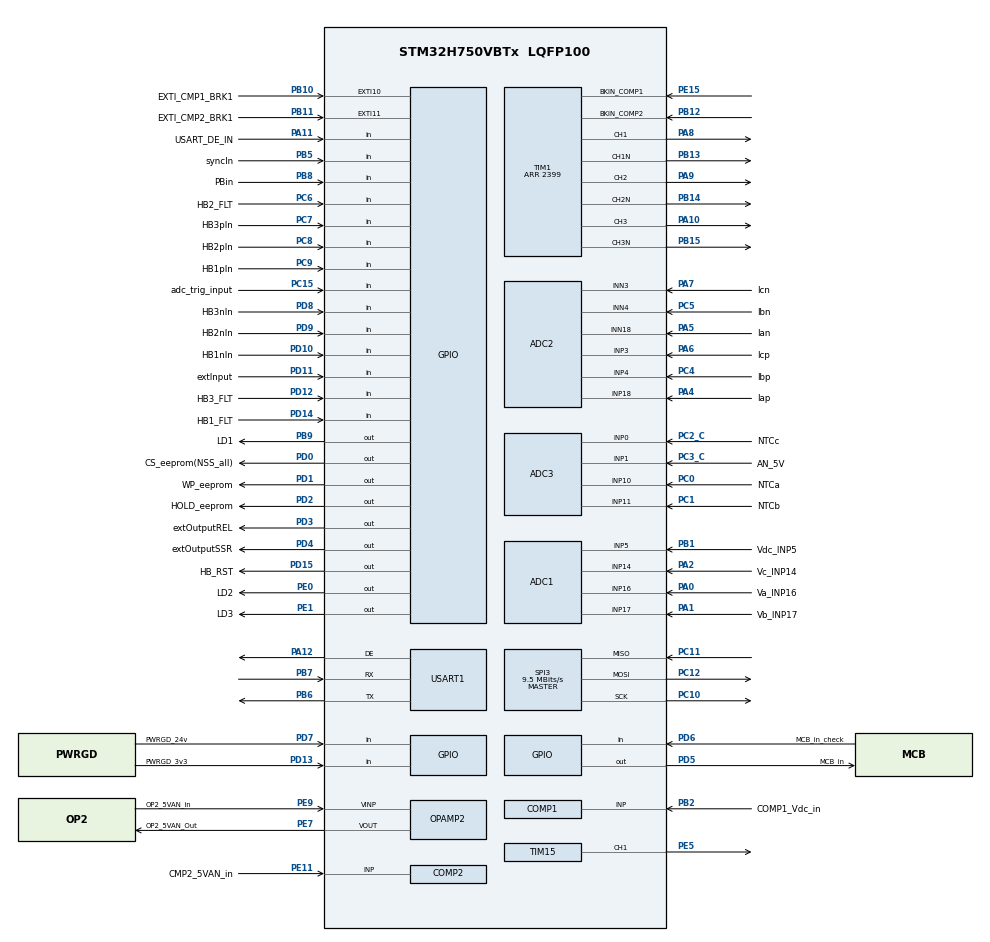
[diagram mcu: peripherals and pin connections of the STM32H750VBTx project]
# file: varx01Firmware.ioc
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ADC1.Channel-1\#ChannelRegularConversion=ADC_CHANNEL_16
ADC1.Channel-2\#ChannelRegularConversion=ADC_CHANNEL_17
ADC1.Channel-3\#ChannelRegularConversion=ADC_CHANNEL_14
ADC1.Channel-4\#ChannelRegularConversion=ADC_CHANNEL_5
ADC1.ConversionDataManagement=ADC_CONVERSIONDATA_DMA_CIRCULAR
ADC1.DMAAccessModeView=ENABLE
ADC1.EOCSelection=ADC_EOC_SEQ_CONV
ADC1.EnableAnalogWatchDog1=false
ADC1.ExternalTrigConv=ADC_EXTERNALTRIG_T2_TRGO
ADC1.Mode=ADC_DUALMODE_REGSIMULT
ADC1.NbrOfConversion=4
ADC1.NbrOfConversionFlag=1
ADC1.OffsetNumber-1\#ChannelRegularConversion=ADC_OFFSET_NONE
ADC1.OffsetNumber-2\#ChannelRegularConversion=ADC_OFFSET_NONE
ADC1.OffsetNumber-3\#ChannelRegularConversion=ADC_OFFSET_NONE
ADC1.OffsetNumber-4\#ChannelRegularConversion=ADC_OFFSET_NONE
ADC1.OffsetSignedSaturation-2\#ChannelRegularConversion=DISABLE
ADC1.OffsetSignedSaturation-3\#ChannelRegularConversion=DISABLE
ADC1.OffsetSignedSaturation-4\#ChannelRegularConversion=DISABLE
ADC1.Overrun=ADC_OVR_DATA_OVERWRITTEN
ADC1.OversamplingMode=ENABLE
ADC1.Rank-1\#ChannelRegularConversion=1
ADC1.Rank-2\#ChannelRegularConversion=2
ADC1.Rank-3\#ChannelRegularConversion=3
ADC1.Rank-4\#ChannelRegularConversion=4
ADC1.Ratio=4
ADC1.RightBitShift=ADC_RIGHTBITSHIFT_2
ADC1.SamplingTime-1\#ChannelRegularConversion=ADC_SAMPLETIME_16CYCLES_5
ADC1.SamplingTime-2\#ChannelRegularConversion=ADC_SAMPLETIME_16CYCLES_5
ADC1.SamplingTime-3\#ChannelRegularConversion=ADC_SAMPLETIME_16CYCLES_5
ADC1.SamplingTime-4\#ChannelRegularConversion=ADC_SAMPLETIME_16CYCLES_5
ADC1.master=1
ADC2.AWD1HighThreshold=158368
ADC2.AWD1ITMode=ENABLE
ADC2.AWD1LowThreshold=103771
ADC2.Channel-0\#ChannelRegularConversion=ADC_CHANNEL_18
ADC2.Channel-1\#ChannelRegularConversion=ADC_CHANNEL_4
ADC2.Channel-2\#ChannelRegularConversion=ADC_CHANNEL_3
ADC2.Channel-3\#ChannelRegularConversion=ADC_CHANNEL_18
ADC2.DMAAccessModeView=ENABLE
ADC2.EOCSelection=ADC_EOC_SEQ_CONV
ADC2.EnableAnalogWatchDog1=true
ADC2.Mode=ADC_DUALMODE_REGSIMULT
ADC2.NbrOfConversion=4
ADC2.NbrOfConversionFlag=1
ADC2.OffsetNumber-0\#ChannelRegularConversion=ADC_OFFSET_NONE
ADC2.OffsetNumber-1\#ChannelRegularConversion=ADC_OFFSET_NONE
ADC2.OffsetNumber-2\#ChannelRegularConversion=ADC_OFFSET_NONE
ADC2.OffsetNumber-3\#ChannelRegularConversion=ADC_OFFSET_NONE
ADC2.OffsetSignedSaturation-1\#ChannelRegularConversion=DISABLE
ADC2.OffsetSignedSaturation-2\#ChannelRegularConversion=DISABLE
ADC2.OffsetSignedSaturation-3\#ChannelRegularConversion=DISABLE
ADC2.Overrun=ADC_OVR_DATA_OVERWRITTEN
ADC2.OversamplingMode=ENABLE
ADC2.Rank-0\#ChannelRegularConversion=1
ADC2.Rank-1\#ChannelRegularConversion=2
ADC2.Rank-2\#ChannelRegularConversion=3
ADC2.Rank-3\#ChannelRegularConversion=4
ADC2.Ratio=4
ADC2.RightBitShift=ADC_RIGHTBITSHIFT_2
ADC2.SamplingTime-0\#ChannelRegularConversion=ADC_SAMPLETIME_16CYCLES_5
ADC2.SamplingTime-1\#ChannelRegularConversion=ADC_SAMPLETIME_16CYCLES_5
ADC2.SamplingTime-2\#ChannelRegularConversion=ADC_SAMPLETIME_16CYCLES_5
ADC2.SamplingTime-3\#ChannelRegularConversion=ADC_SAMPLETIME_16CYCLES_5
ADC2.SingleDiff-0\#ChannelRegularConversion=ADC_DIFFERENTIAL_ENDED
ADC2.SingleDiff-1\#ChannelRegularConversion=ADC_DIFFERENTIAL_ENDED
ADC2.SingleDiff-2\#ChannelRegularConversion=ADC_DIFFERENTIAL_ENDED
ADC2.SingleDiff-3\#ChannelRegularConversion=ADC_DIFFERENTIAL_ENDED
ADC2.WatchdogMode=ADC_ANALOGWATCHDOG_ALL_REG
ADC3.Channel-0\#ChannelRegularConversion=ADC_CHANNEL_10
ADC3.Channel-1\#ChannelRegularConversion=ADC_CHANNEL_11
ADC3.Channel-2\#ChannelRegularConversion=ADC_CHANNEL_0
ADC3.Channel-3\#ChannelRegularConversion=ADC_CHANNEL_1
ADC3.ClockPrescaler=ADC_CLOCK_ASYNC_DIV1
ADC3.ConversionDataManagement=ADC_CONVERSIONDATA_DMA_CIRCULAR
ADC3.EOCSelection=ADC_EOC_SEQ_CONV
ADC3.EnableAnalogWatchDog1=false
ADC3.ExternalTrigConv=ADC_EXTERNALTRIG_T4_TRGO
ADC3.NbrOfConversion=4
ADC3.NbrOfConversionFlag=1
ADC3.OffsetNumber-0\#ChannelRegularConversion=ADC_OFFSET_NONE
ADC3.OffsetNumber-1\#ChannelRegularConversion=ADC_OFFSET_NONE
ADC3.OffsetNumber-2\#ChannelRegularConversion=ADC_OFFSET_NONE
ADC3.OffsetNumber-3\#ChannelRegularConversion=ADC_OFFSET_NONE
ADC3.OffsetSignedSaturation-1\#ChannelRegularConversion=DISABLE
ADC3.OffsetSignedSaturation-2\#ChannelRegularConversion=DISABLE
ADC3.OffsetSignedSaturation-3\#ChannelRegularConversion=DISABLE
ADC3.Overrun=ADC_OVR_DATA_OVERWRITTEN
ADC3.OversamplingMode=ENABLE
ADC3.Rank-0\#ChannelRegularConversion=1
ADC3.Rank-1\#ChannelRegularConversion=2
ADC3.Rank-2\#ChannelRegularConversion=3
ADC3.Rank-3\#ChannelRegularConversion=4
ADC3.Ratio=4
ADC3.RightBitShift=ADC_RIGHTBITSHIFT_2
ADC3.SamplingTime-0\#ChannelRegularConversion=ADC_SAMPLETIME_16CYCLES_5
ADC3.SamplingTime-1\#ChannelRegularConversion=ADC_SAMPLETIME_16CYCLES_5
ADC3.SamplingTime-2\#ChannelRegularConversion=ADC_SAMPLETIME_16CYCLES_5
ADC3.SamplingTime-3\#ChannelRegularConversion=ADC_SAMPLETIME_16CYCLES_5
COMP1.TriggerMode=COMP_TRIGGERMODE_IT_RISING
COMP2.TriggerMode=COMP_TRIGGERMODE_IT_RISING
CORTEX_M7.CPU_DCache=Enabled
CORTEX_M7.CPU_ICache=Enabled
DAC1.DAC_Channel-DAC_OUT1_Int=DAC_CHANNEL_1
DAC1.DAC_Channel-DAC_OUT2_Int=DAC_CHANNEL_2
Dma.ADC1.0.Direction=DMA_PERIPH_TO_MEMORY
Dma.ADC1.0.EventEnable=DISABLE
Dma.ADC1.0.FIFOMode=DMA_FIFOMODE_DISABLE
Dma.ADC1.0.Instance=DMA1_Stream0
Dma.ADC1.0.MemDataAlignment=DMA_MDATAALIGN_WORD
Dma.ADC1.0.MemInc=DMA_MINC_ENABLE
Dma.ADC1.0.Mode=DMA_CIRCULAR
Dma.ADC1.0.PeriphDataAlignment=DMA_PDATAALIGN_WORD
Dma.ADC1.0.PeriphInc=DMA_PINC_DISABLE
Dma.ADC1.0.Polarity=HAL_DMAMUX_REQ_GEN_RISING
Dma.ADC1.0.Priority=DMA_PRIORITY_VERY_HIGH
Dma.ADC1.0.RequestNumber=1
Dma.ADC1.0.SignalID=NONE
Dma.ADC1.0.SyncEnable=DISABLE
Dma.ADC1.0.SyncPolarity=HAL_DMAMUX_SYNC_NO_EVENT
Dma.ADC1.0.SyncRequestNumber=1
Dma.ADC1.0.SyncSignalID=NONE
Dma.ADC3.1.Direction=DMA_PERIPH_TO_MEMORY
Dma.ADC3.1.EventEnable=DISABLE
Dma.ADC3.1.FIFOMode=DMA_FIFOMODE_DISABLE
Dma.ADC3.1.Instance=DMA2_Stream1
Dma.ADC3.1.MemDataAlignment=DMA_MDATAALIGN_WORD
Dma.ADC3.1.MemInc=DMA_MINC_ENABLE
Dma.ADC3.1.Mode=DMA_CIRCULAR
Dma.ADC3.1.PeriphDataAlignment=DMA_PDATAALIGN_WORD
Dma.ADC3.1.PeriphInc=DMA_PINC_DISABLE
Dma.ADC3.1.Polarity=HAL_DMAMUX_REQ_GEN_RISING
Dma.ADC3.1.Priority=DMA_PRIORITY_LOW
Dma.ADC3.1.RequestNumber=1
Dma.ADC3.1.SignalID=NONE
Dma.ADC3.1.SyncEnable=DISABLE
Dma.ADC3.1.SyncPolarity=HAL_DMAMUX_SYNC_NO_EVENT
Dma.ADC3.1.SyncRequestNumber=1
Dma.ADC3.1.SyncSignalID=NONE
Dma.Request0=ADC1
Dma.Request1=ADC3
Mcu.Family=STM32H7
Mcu.Name=STM32H750VBTx
Mcu.Package=LQFP100
NVIC.COMP_IRQn=true\:0\:0\:false\:false\:true\:false\:true
NVIC.DMA1_Stream0_IRQn=true\:0\:0\:false\:false\:true\:false\:true
NVIC.DMA2_Stream1_IRQn=true\:0\:0\:false\:false\:true\:false\:true
NVIC.PriorityGroup=NVIC_PRIORITYGROUP_4
NVIC.TIM1_BRK_IRQn=true\:0\:0\:false\:false\:true\:true\:true
NVIC.TIM1_CC_IRQn=true\:0\:0\:false\:false\:true\:true\:true
NVIC.TIM2_IRQn=true\:0\:0\:false\:false\:true\:true\:true
NVIC.TIM4_IRQn=true\:0\:0\:false\:false\:true\:true\:true
PA0.GPIO_Label=Va_INP16
PA0.Mode=IN16-Single-Ended
PA0.Signal=ADC1_INP16
PA1.GPIO_Label=Vb_INP17
PA1.Mode=IN17-Single-Ended
PA1.Signal=ADC1_INP17
PA10.Signal=S_TIM1_CH3
PA11.GPIO_Label=USART_DE_IN
PA11.Signal=GPIO_Input
PA12.Mode=Hardware Flow Control (RS485)
PA12.Signal=USART1_DE
PA13\ (JTMS/SWDIO).Mode=JTAG_5_pins
PA13\ (JTMS/SWDIO).Signal=DEBUG_JTMS-SWDIO
PA14\ (JTCK/SWCLK).Mode=JTAG_5_pins
PA14\ (JTCK/SWCLK).Signal=DEBUG_JTCK-SWCLK
PA15\ (JTDI).GPIO_Label=DEBUG_JTDI(SPI3_NSS)
PA15\ (JTDI).Mode=JTAG_5_pins
PA15\ (JTDI).Signal=DEBUG_JTDI
PA2.GPIO_Label=Vc_INP14
PA2.Signal=ADCx_INP14
PA4.GPIO_Label=Iap
PA4.Signal=ADCx_INP18
PA5.GPIO_Label=Ian
PA5.Signal=ADCx_INN18
PA6.GPIO_Label=Icp
PA6.Signal=ADCx_INP3
PA7.GPIO_Label=Icn
PA7.Signal=ADCx_INN3
PA8.Signal=S_TIM1_CH1
PA9.Signal=S_TIM1_CH2
PB1.GPIO_Label=Vdc_INP5
PB1.Signal=ADCx_INP5
PB10.GPIO_Label=EXTI_CMP1_BRK1
PB10.Signal=GPXTI10
PB11.GPIO_Label=EXTI_CMP2_BRK1
PB11.Signal=GPXTI11
PB12.Mode=ExternalOutput_TIM1BKIN
PB12.Signal=TIM1_BKIN_COMP2
PB13.Mode=PWM Generation1 CH1 CH1N
PB13.Signal=TIM1_CH1N
PB14.Mode=PWM Generation2 CH2 CH2N
PB14.Signal=TIM1_CH2N
PB15.Mode=PWM Generation3 CH3 CH3N
PB15.Signal=TIM1_CH3N
PB2.GPIO_Label=COMP1_Vdc_in
PB2.Mode=INP
PB2.Signal=COMP1_INP
PB3\ (JTDO/TRACESWO).Mode=JTAG_5_pins
PB3\ (JTDO/TRACESWO).Signal=DEBUG_JTDO-SWO
PB4\ (NJTRST).Mode=JTAG_5_pins
PB4\ (NJTRST).Signal=DEBUG_JTRST
PB5.GPIO_Label=syncIn
PB5.Signal=GPIO_Input
PB6.Mode=Asynchronous
PB6.Signal=USART1_TX
PB7.Mode=Asynchronous
PB7.Signal=USART1_RX
PB8.GPIO_Label=PBin
PB8.Signal=GPIO_Input
PB9.GPIO_Label=LD1
PB9.Signal=GPIO_Output
PC0.GPIO_Label=NTCa
PC0.Signal=ADCx_INP10
PC1.GPIO_Label=NTCb
PC1.Signal=ADCx_INP11
PC10.Mode=Full_Duplex_Master
PC10.Signal=SPI3_SCK
PC11.Mode=Full_Duplex_Master
PC11.Signal=SPI3_MISO
PC12.Mode=Full_Duplex_Master
PC12.Signal=SPI3_MOSI
PC15-OSC32_OUT\ (OSC32_OUT).GPIO_Label=adc_trig_input
PC15-OSC32_OUT\ (OSC32_OUT).Signal=GPIO_Input
PC2_C.GPIO_Label=NTCc
PC2_C.Mode=IN0-Single-Ended
PC2_C.Signal=ADC3_INP0
PC3_C.GPIO_Label=AN_5V
PC3_C.Mode=IN1-Single-Ended
PC3_C.Signal=ADC3_INP1
PC4.GPIO_Label=Ibp
PC4.Signal=ADCx_INP4
PC5.GPIO_Label=Ibn
PC5.Signal=ADCx_INN4
PC6.GPIO_Label=HB2_FLT
PC6.Signal=GPIO_Input
PC7.GPIO_Label=HB3pIn
PC7.Signal=GPIO_Input
PC8.GPIO_Label=HB2pIn
PC8.Signal=GPIO_Input
PC9.GPIO_Label=HB1pIn
PC9.Signal=GPIO_Input
PD0.GPIO_Label=CS_eeprom(NSS_all)
PD0.Signal=GPIO_Output
PD1.GPIO_Label=WP_eeprom
PD1.Signal=GPIO_Output
PD10.GPIO_Label=HB1nIn
PD10.Signal=GPIO_Input
PD11.GPIO_Label=extInput
PD11.Signal=GPIO_Input
PD12.GPIO_Label=HB3_FLT
PD12.Signal=GPIO_Input
PD13.GPIO_Label=PWRGD_3v3
PD13.Signal=GPIO_Input
PD14.GPIO_Label=HB1_FLT
PD14.Signal=GPIO_Input
PD15.GPIO_Label=HB_RST
PD15.Signal=GPIO_Output
PD2.GPIO_Label=HOLD_eeprom
PD2.Signal=GPIO_Output
PD3.GPIO_Label=extOutputREL
PD3.Signal=GPIO_Output
PD4.GPIO_Label=extOutputSSR
PD4.Signal=GPIO_Output
PD5.GPIO_Label=MCB_in
PD5.Signal=GPIO_Output
PD6.GPIO_Label=MCB_in_check
PD6.Signal=GPIO_Input
PD7.GPIO_Label=PWRGD_24v
PD7.Signal=GPIO_Input
PD8.GPIO_Label=HB3nIn
PD8.Signal=GPIO_Input
PD9.GPIO_Label=HB2nIn
PD9.Signal=GPIO_Input
PE0.GPIO_Label=LD2
PE0.Signal=GPIO_Output
PE1.GPIO_Label=LD3
PE1.Signal=GPIO_Output
PE11.GPIO_Label=CMP2_5VAN_in
PE11.Mode=INP
PE11.Signal=COMP2_INP
PE15.Mode=ExternalOutput_TIM1BKIN
PE15.Signal=TIM1_BKIN_COMP1
PE5.Signal=S_TIM15_CH1
PE7.GPIO_Label=OP2_5VAN_Out
PE7.Mode=Follower
PE7.Signal=OPAMP2_VOUT
PE9.GPIO_Label=OP2_5VAN_in
PE9.Mode=Follower
PE9.Signal=OPAMP2_VINP
PH0-OSC_IN\ (PH0).Mode=HSE-External-Oscillator
PH0-OSC_IN\ (PH0).Signal=RCC_OSC_IN
PH1-OSC_OUT\ (PH1).Mode=HSE-External-Oscillator
PH1-OSC_OUT\ (PH1).Signal=RCC_OSC_OUT
ProjectManager.HeapSize=0x200
ProjectManager.StackSize=0x400
ProjectManager.TargetToolchain=MDK-ARM V5
RCC.ADCFreq_Value=76000000
RCC.APB1Freq_Value=120000000
RCC.APB2Freq_Value=120000000
RCC.APB3Freq_Value=120000000
RCC.APB4Freq_Value=120000000
RCC.CortexFreq_Value=480000000
RCC.D1PPRE=RCC_APB3_DIV2
RCC.D2PPRE1=RCC_APB1_DIV2
RCC.D2PPRE2=RCC_APB2_DIV2
RCC.D3PPRE=RCC_APB4_DIV2
RCC.DIVM1=1
RCC.DIVM2=1
RCC.DIVM3=1
RCC.DIVN1=120
RCC.DIVN2=19
RCC.DIVN3=32
RCC.DIVQ2=1
RCC.HCLKFreq_Value=240000000
RCC.HPRE=RCC_HCLK_DIV2
RCC.HSE_VALUE=8000000
RCC.PLL2FRACN=0
RCC.PLLSourceVirtual=RCC_PLLSOURCE_HSE
RCC.SPI123CLockSelection=RCC_SPI123CLKSOURCE_PLL2
RCC.SYSCLKFreq_VALUE=480000000
RCC.SYSCLKSource=RCC_SYSCLKSOURCE_PLLCLK
RCC.USBFreq_Value=480000000
SH.ADCx_INN18.0=ADC2_INN18,IN18-Differential
SH.ADCx_INN3.0=ADC2_INN3,IN3-Differential
SH.ADCx_INN4.0=ADC2_INN4,IN4-Differential
SH.ADCx_INP10.0=ADC3_INP10,IN10-Single-Ended
SH.ADCx_INP11.0=ADC3_INP11,IN11-Single-Ended
SH.ADCx_INP14.0=ADC1_INP14,IN14-Single-Ended
SH.ADCx_INP18.0=ADC2_INP18,IN18-Differential
SH.ADCx_INP3.0=ADC2_INP3,IN3-Differential
SH.ADCx_INP4.0=ADC2_INP4,IN4-Differential
SH.ADCx_INP5.0=ADC1_INP5,IN5-Single-Ended
SH.S_TIM15_CH1.0=TIM15_CH1,Output Compare1 CH1
SH.S_TIM1_CH1.0=TIM1_CH1,PWM Generation1 CH1 CH1N
SH.S_TIM1_CH2.0=TIM1_CH2,PWM Generation2 CH2 CH2N
SH.S_TIM1_CH3.0=TIM1_CH3,PWM Generation3 CH3 CH3N
SPI3.BaudRatePrescaler=SPI_BAUDRATEPRESCALER_8
SPI3.CalculateBaudRate=9.5 MBits/s
SPI3.Direction=SPI_DIRECTION_2LINES
SPI3.Mode=SPI_MODE_MASTER
SPI3.VirtualType=VM_MASTER
TIM1.AutoReloadPreload=TIM_AUTORELOAD_PRELOAD_ENABLE
TIM1.AutomaticOutput=TIM_AUTOMATICOUTPUT_ENABLE
TIM1.BreakState=TIM_BREAK_DISABLE
TIM1.Channel-PWM\ Generation1\ CH1\ CH1N=TIM_CHANNEL_1
TIM1.Channel-PWM\ Generation2\ CH2\ CH2N=TIM_CHANNEL_2
TIM1.Channel-PWM\ Generation3\ CH3\ CH3N=TIM_CHANNEL_3
TIM1.CounterMode=TIM_COUNTERMODE_CENTERALIGNED1
TIM1.DeadTime=30
TIM1.OffStateIDLEMode=TIM_OSSI_DISABLE
TIM1.OffStateRunMode=TIM_OSSR_DISABLE
TIM1.Period=2399
TIM1.SourceBRKCOMP1=TIM_BREAKINPUTSOURCE_DISABLE
TIM1.SourceBRKCOMP2=TIM_BREAKINPUTSOURCE_ENABLE
TIM1.SourceBRKCOMP2Polarity=TIM_BREAKINPUTSOURCE_POLARITY_HIGH
TIM15.Channel-Output\ Compare1\ CH1=TIM_CHANNEL_1
TIM2.Period=4799
TIM2.TIM_MasterOutputTrigger=TIM_TRGO_UPDATE
TIM4.Period=47999
TIM4.Prescaler=4
TIM4.TIM_MasterOutputTrigger=TIM_TRGO_UPDATE
USART1.VirtualMode-Asynchronous=VM_ASYNC
USART1.VirtualMode-Hardware\ Flow\ Control\ (RS485)=VM_ASYNC
VP_COMP1_VS_DACOUT1.Mode=INM_DACOUT1
VP_COMP2_VS_DACOUT2.Mode=INM_DACOUT2
VP_DAC1_VS_DACI1.Mode=DAC_OUT1_Int
VP_DAC1_VS_DACI2.Mode=DAC_OUT2_Int
VP_TIM1_VS_BKIN_COMP2.Mode=Activate-Break-Input-COMP2
VP_TIM2_VS_ClockSourceINT.Mode=Internal
VP_TIM4_VS_ClockSourceINT.Mode=Internal
board=custom

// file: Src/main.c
/* USER CODE BEGIN Header */
/**
  ******************************************************************************
  * @file           : main.c
  * @brief          : Main program body
  ******************************************************************************
  * @attention
  *
  * <h2><center>&copy; Copyright (c) 2021 STMicroelectronics.
  * All rights reserved.</center></h2>
  *
  * This software component is licensed by ST under BSD 3-Clause license,
  * the "License"; You may not use this file except in compliance with the
  * License. You may obtain a copy of the License at:
  *                        opensource.org/licenses/BSD-3-Clause
  *
  ******************************************************************************
  */
/* USER CODE END Header */
#include "main.h"
#include "adc.h"
#include "comp.h"
#include "dac.h"
#include "dma.h"
#include "opamp.h"
#include "spi.h"
#include "tim.h"
#include "usart.h"
#include "gpio.h"

/* USER CODE BEGIN Includes */
#include "initialization.h"
#include "adcHandling.h"
#include "pwmGeneration.h"
#include "LEDs.h"

/* USER CODE END Includes */

/* USER CODE BEGIN PV */

uint8_t dummyCheck=0;

/* USER CODE END PV */

void SystemClock_Config(void);
void PeriphCommonClock_Config(void);

int main(void)
{

  /* Enable I-Cache---------------------------------------------------------*/
  SCB_EnableICache();

  /* Enable D-Cache---------------------------------------------------------*/
  SCB_EnableDCache();

  /* MCU Configuration--------------------------------------------------------*/

  /* Reset of all peripherals, Initializes the Flash interface and the Systick. */
  HAL_Init();

  /* Configure the system clock */
  SystemClock_Config();

/* Configure the peripherals common clocks */
  PeriphCommonClock_Config();

  /* Initialize all configured peripherals */
  MX_GPIO_Init();
  MX_DMA_Init();
  MX_ADC1_Init();
  MX_ADC2_Init();
  MX_ADC3_Init();
  MX_COMP1_Init();
  MX_COMP2_Init();
  MX_DAC1_Init();
  MX_OPAMP2_Init();
  MX_SPI3_Init();
  MX_TIM1_Init();
  MX_TIM15_Init();
  MX_USART1_UART_Init();
  MX_TIM2_Init();
  MX_TIM4_Init();
  /* USER CODE BEGIN 2 */

	initialization();

  /* USER CODE END 2 */

  /* Infinite loop */
  while (1)
  {

    /* USER CODE BEGIN 3 */

		LEDs();

  }
  /* USER CODE END 3 */
}

void SystemClock_Config(void)
{
  RCC_OscInitTypeDef RCC_OscInitStruct = {0};
  RCC_ClkInitTypeDef RCC_ClkInitStruct = {0};

  /** Supply configuration update enable
  */
  HAL_PWREx_ConfigSupply(PWR_LDO_SUPPLY);
  /** Configure the main internal regulator output voltage
  */
  __HAL_PWR_VOLTAGESCALING_CONFIG(PWR_REGULATOR_VOLTAGE_SCALE0);

  while(!__HAL_PWR_GET_FLAG(PWR_FLAG_VOSRDY)) {}
  /** Macro to configure the PLL clock source
  */
  __HAL_RCC_PLL_PLLSOURCE_CONFIG(RCC_PLLSOURCE_HSE);
  /** Initializes the RCC Oscillators according to the specified parameters
  * in the RCC_OscInitTypeDef structure.
  */
  RCC_OscInitStruct.OscillatorType = RCC_OSCILLATORTYPE_HSE;
  RCC_OscInitStruct.HSEState = RCC_HSE_ON;
  RCC_OscInitStruct.PLL.PLLState = RCC_PLL_ON;
  RCC_OscInitStruct.PLL.PLLSource = RCC_PLLSOURCE_HSE;
  RCC_OscInitStruct.PLL.PLLM = 1;
  RCC_OscInitStruct.PLL.PLLN = 120;
  RCC_OscInitStruct.PLL.PLLP = 2;
  RCC_OscInitStruct.PLL.PLLQ = 2;
  RCC_OscInitStruct.PLL.PLLR = 2;
  RCC_OscInitStruct.PLL.PLLRGE = RCC_PLL1VCIRANGE_3;
  RCC_OscInitStruct.PLL.PLLVCOSEL = RCC_PLL1VCOWIDE;
  RCC_OscInitStruct.PLL.PLLFRACN = 0;
  if (HAL_RCC_OscConfig(&RCC_OscInitStruct) != HAL_OK)
  {
    Error_Handler();
  }
  /** Initializes the CPU, AHB and APB buses clocks
  */
  RCC_ClkInitStruct.ClockType = RCC_CLOCKTYPE_HCLK|RCC_CLOCKTYPE_SYSCLK
                              |RCC_CLOCKTYPE_PCLK1|RCC_CLOCKTYPE_PCLK2
                              |RCC_CLOCKTYPE_D3PCLK1|RCC_CLOCKTYPE_D1PCLK1;
  RCC_ClkInitStruct.SYSCLKSource = RCC_SYSCLKSOURCE_PLLCLK;
  RCC_ClkInitStruct.SYSCLKDivider = RCC_SYSCLK_DIV1;
  RCC_ClkInitStruct.AHBCLKDivider = RCC_HCLK_DIV2;
  RCC_ClkInitStruct.APB3CLKDivider = RCC_APB3_DIV2;
  RCC_ClkInitStruct.APB1CLKDivider = RCC_APB1_DIV2;
  RCC_ClkInitStruct.APB2CLKDivider = RCC_APB2_DIV2;
  RCC_ClkInitStruct.APB4CLKDivider = RCC_APB4_DIV2;

  if (HAL_RCC_ClockConfig(&RCC_ClkInitStruct, FLASH_LATENCY_4) != HAL_OK)
  {
    Error_Handler();
  }
}

void PeriphCommonClock_Config(void)
{
  RCC_PeriphCLKInitTypeDef PeriphClkInitStruct = {0};

  /** Initializes the peripherals clock
  */
  PeriphClkInitStruct.PeriphClockSelection = RCC_PERIPHCLK_ADC|RCC_PERIPHCLK_SPI3;
  PeriphClkInitStruct.PLL2.PLL2M = 1;
  PeriphClkInitStruct.PLL2.PLL2N = 19;
  PeriphClkInitStruct.PLL2.PLL2P = 2;
  PeriphClkInitStruct.PLL2.PLL2Q = 1;
  PeriphClkInitStruct.PLL2.PLL2R = 2;
  PeriphClkInitStruct.PLL2.PLL2RGE = RCC_PLL2VCIRANGE_3;
  PeriphClkInitStruct.PLL2.PLL2VCOSEL = RCC_PLL2VCOMEDIUM;
  PeriphClkInitStruct.PLL2.PLL2FRACN = 0;
  PeriphClkInitStruct.Spi123ClockSelection = RCC_SPI123CLKSOURCE_PLL2;
  PeriphClkInitStruct.AdcClockSelection = RCC_ADCCLKSOURCE_PLL2;
  if (HAL_RCCEx_PeriphCLKConfig(&PeriphClkInitStruct) != HAL_OK)
  {
    Error_Handler();
  }
}

void Error_Handler(void)
{
  __disable_irq();
  while (1)
  {
  }
}

/************************ (C) COPYRIGHT STMicroelectronics *****END OF FILE****/
